VERSION ""

NS_ :

BS_:
BU_: TMS
BO_ 386 FLOW_TPDO: 4 TMS
   SG_ TPDO2Flow1 : 0|16@1- (1,0) [0|255] "duty_cycle" TMS
   SG_ TPDO2Flow2 : 16|16@1- (1,0) [0|255] "duty_cycle" TMS

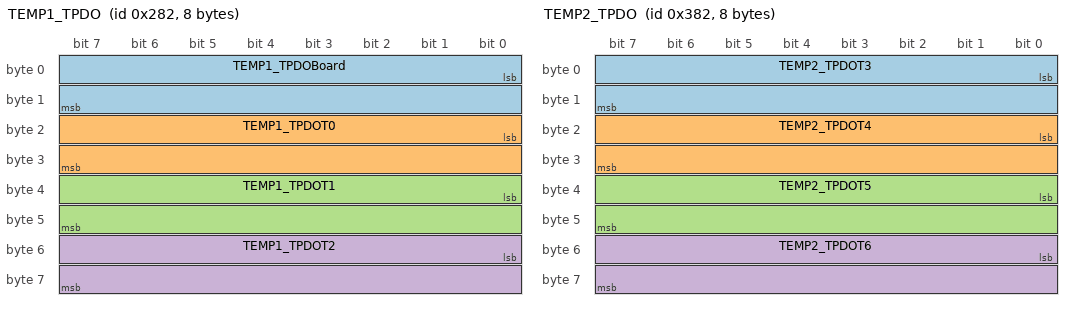
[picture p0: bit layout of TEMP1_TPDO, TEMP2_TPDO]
BO_ 642 TEMP1_TPDO: 8 TMS
   SG_ TEMP1_TPDOBoard : 0|16@1- (1,0) [-25600|25599] "centiCelcius" TMS
   SG_ TEMP1_TPDOT0 : 16|16@1- (1,0) [-25600|25599] "centiCelcius" TMS
   SG_ TEMP1_TPDOT1 : 32|16@1- (1,0) [-25600|25599] "centiCelcius" TMS
   SG_ TEMP1_TPDOT2 : 48|16@1- (1,0) [-25600|25599] "centiCelcius" TMS

BO_ 898 TEMP2_TPDO: 8 TMS
   SG_ TEMP2_TPDOT3 : 0|16@1- (1,0) [-25600|25599] "centiCelcius" TMS
   SG_ TEMP2_TPDOT4 : 16|16@1- (1,0) [-25600|25599] "centiCelcius" TMS
   SG_ TEMP2_TPDOT5 : 32|16@1- (1,0) [-25600|25599] "centiCelcius" TMS
   SG_ TEMP2_TPDOT6 : 48|16@1- (1,0) [-25600|25599] "centiCelcius" TMS

BO_ 1794 Heartbeat: 1 TMS
   SG_ HeartbeatSig : 7|8@0+ (1,0) [0|127] "" TMS

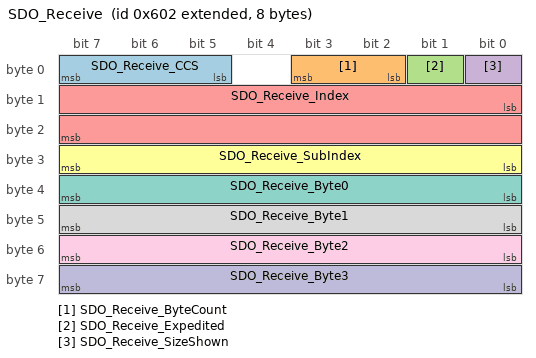
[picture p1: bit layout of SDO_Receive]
BO_ 2147485186 SDO_Receive: 8 TMS
   SG_ SDO_Receive_CCS : 5|3@1+ (1,0) [0|255] "" TMS
   SG_ SDO_Receive_ByteCount : 2|2@1+ (1,0) [0|255] "" TMS
   SG_ SDO_Receive_Expedited : 1|1@1+ (1,0) [0|1] "" TMS
   SG_ SDO_Receive_SizeShown : 0|1@1+ (1,0) [0|1] "" TMS
   SG_ SDO_Receive_Index : 8|16@1+ (1,0) [0|255] "" TMS
   SG_ SDO_Receive_SubIndex : 24|8@1+ (1,0) [0|255] "" TMS
   SG_ SDO_Receive_Byte0 : 32|8@1+ (1,0) [0|255] "" Vector__XXX
   SG_ SDO_Receive_Byte1 : 40|8@1+ (1,0) [0|255] "" Vector__XXX
   SG_ SDO_Receive_Byte2 : 48|8@1+ (1,0) [0|255] "" Vector__XXX
   SG_ SDO_Receive_Byte3 : 56|8@1+ (1,0) [0|255] "" Vector__XXX

BO_ 2147485058 SDO_TRANSMIT: 8 TMS

BO_ 2147484288 RPDO0_VCU_TPDO1: 2 TMS
   SG_ RPDO0_VCU_TPDO1Pump1 : 0|8@1+ (1,0) [0|100] "" Vector__XXX
   SG_ RPDO0_VCU_TPDO1Pump2 : 8|8@1+ (1,0) [0|100] "" Vector__XXX

CM_ SG_ 2147485186 SDO_Receive_CCS "Command_Byte";
CM_ SG_ 2147485186 SDO_Receive_ByteCount "Command_Byte";
CM_ SG_ 2147485186 SDO_Receive_Expedited "Command_Byte";
CM_ SG_ 2147485186 SDO_Receive_SizeShown "Command_Byte";
CM_ BO_ 2147484288 "TEMPORARY PUMP CONTROL! Use SDO instead.";
BA_DEF_ BO_ "GenMsgBackgroundColor" STRING ;
BA_DEF_ BO_ "GenMsgForegroundColor" STRING ;
BA_DEF_ BO_ "filterlabeling" INT 0 0;
BA_DEF_ BO_ "filterlabeling" INT 0 0;
BA_DEF_ BO_ "filterlabeling" INT 0 0;
BA_DEF_DEF_ "GenMsgBackgroundColor" "#ffffff";
BA_DEF_DEF_ "GenMsgForegroundColor" "#000000";
BA_DEF_DEF_ "filterlabeling" 1;
BA_ "GenMsgForegroundColor" BO_ 1794 "#aa00ff";
BA_ "GenMsgForegroundColor" BO_ 2147485186 "#0000ff";
BA_ "GenMsgForegroundColor" BO_ 2147485058 "#0000ff";
BA_ "GenMsgForegroundColor" BO_ 2147484288 "#ff0000";
VAL_ 1794 HeartbeatSig 0 "Bootup" 4 "Stopped" 5 "Operational" 127 "Pre-Operationa";
VAL_ 2147485186 SDO_Receive_CCS 1 "Download" 2 "Upload";
VAL_ 2147485186 SDO_Receive_ByteCount 0 "4_Bytes" 1 "3_Bytes" 2 "2_Bytes" 3 "1_Byte";
